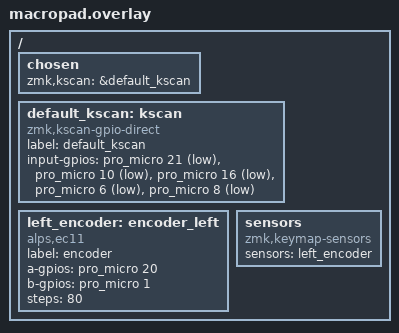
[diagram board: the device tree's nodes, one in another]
/ {
    chosen {
        zmk,kscan = &default_kscan;
    };

    default_kscan: kscan {
        compatible = "zmk,kscan-gpio-direct";
        label = "default_kscan";

        input-gpios =
            <&pro_micro 21 (GPIO_ACTIVE_LOW | GPIO_PULL_UP)>,
            <&pro_micro 10 (GPIO_ACTIVE_LOW | GPIO_PULL_UP)>,
            <&pro_micro 16 (GPIO_ACTIVE_LOW | GPIO_PULL_UP)>,
            <&pro_micro 6 (GPIO_ACTIVE_LOW | GPIO_PULL_UP)>,
            <&pro_micro 8 (GPIO_ACTIVE_LOW | GPIO_PULL_UP)>;
    };

    left_encoder: encoder_left {
        compatible = "alps,ec11";
        label = "encoder";
        a-gpios = <&pro_micro 20 (GPIO_ACTIVE_HIGH | GPIO_PULL_UP)>;
        b-gpios = <&pro_micro 1 (GPIO_ACTIVE_HIGH | GPIO_PULL_UP)>;
        steps = <80>;
        status = "okay";
    };

    sensors {
        compatible = "zmk,keymap-sensors";
        sensors = <&left_encoder>;
    };
};
